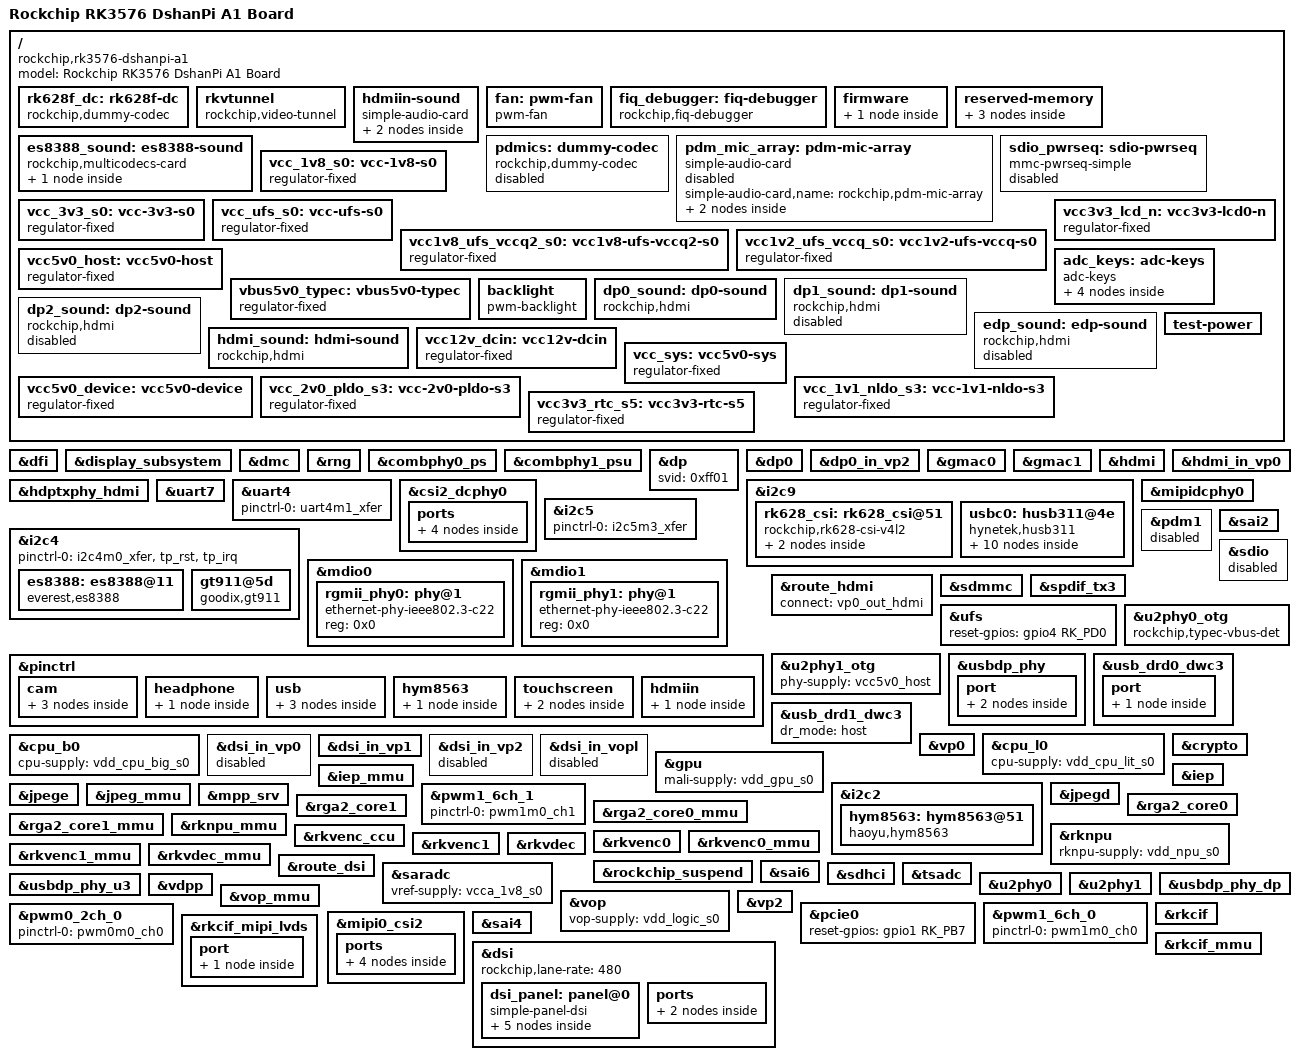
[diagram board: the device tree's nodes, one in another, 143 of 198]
// SPDX-License-Identifier: (GPL-2.0+ OR MIT)
/*
 * Copyright (c) 2024 Rockchip Electronics Co., Ltd.
 *
 */

/dts-v1/;

#include "rk3576.dtsi"
#include <dt-bindings/gpio/gpio.h>
#include <dt-bindings/pwm/pwm.h>
#include <dt-bindings/pinctrl/rockchip.h>
#include <dt-bindings/input/rk-input.h>
#include <dt-bindings/display/drm_mipi_dsi.h>
#include <dt-bindings/display/rockchip_vop.h>
#include <dt-bindings/sensor-dev.h>
#include <dt-bindings/usb/pd.h>
#include "rk3576-rk806.dtsi"

/ {

	model = "Rockchip RK3576 DshanPi A1 Board";
	compatible = "rockchip,rk3576-dshanpi-a1", "rockchip,rk3576";
	
	/delete-node/ chosen;
	
	rk628f_dc: rk628f-dc {
			compatible = "rockchip,dummy-codec";
			#sound-dai-cells = <0>;
			/*status = "okay";*/
	};

	rkvtunnel: rkvtunnel {
			compatible = "rockchip,video-tunnel";
			status = "okay";
	};

	hdmiin-sound {
			compatible = "simple-audio-card";
			simple-audio-card,format = "i2s";
			simple-audio-card,name = "rockchip,hdmiin";
			simple-audio-card,bitclock-master = <&dailink0_master>;
			simple-audio-card,frame-master = <&dailink0_master>;
			status = "okay";
			simple-audio-card,cpu {
					sound-dai = <&sai4>;
			};
			dailink0_master: simple-audio-card,codec {
					sound-dai = <&rk628f_dc>;
			};
	};

	fan: pwm-fan {
		status = "okay";
		compatible = "pwm-fan";
		#cooling-cells = <2>;
		pwms = <&pwm1_6ch_0 0 50000 1>;
		
		cooling-levels = <0 100 125 150 200 255>;
		
		rockchip,temp-trips = <
			40000    1
			50000    2
			60000    3
			65000    4
			70000    5
		>;
	};

	fiq_debugger: fiq-debugger {
		compatible = "rockchip,fiq-debugger";
		rockchip,serial-id = <0>;
		rockchip,wake-irq = <0>;
		/* If enable uart uses irq instead of fiq */
		rockchip,irq-mode-enable = <1>;
		rockchip,baudrate = <1500000>;  /* Only 115200 and 1500000 */
		interrupts = <GIC_SPI 389 IRQ_TYPE_LEVEL_LOW>;
		pinctrl-names = "default";
		pinctrl-0 = <&uart0m0_xfer>;
		status = "okay";
	};

	firmware {
		optee: optee {
			compatible = "linaro,optee-tz";
			method = "smc";
		};
	};

	reserved-memory {
		#address-cells = <2>;
		#size-cells = <2>;
		ranges;

		drm_logo: drm-logo@0 {
			compatible = "rockchip,drm-logo";
			reg = <0x0 0x0 0x0 0x0>;
		};

		drm_cubic_lut: drm-cubic-lut@0 {
			compatible = "rockchip,drm-cubic-lut";
			reg = <0x0 0x0 0x0 0x0>;
		};

		ramoops: ramoops@40110000 {
			compatible = "ramoops";
			/* 0x40110000 to 0x401f0000 is for ramoops */
			reg = <0x0 0x40110000 0x0 0xe0000>;
			boot-log-size = <0x8000>;	/* do not change */
			boot-log-count = <0x1>;		/* do not change */
			console-size = <0x80000>;
			pmsg-size = <0x30000>;
			ftrace-size = <0x00000>;
			record-size = <0x14000>;
		};
	};

	es8388_sound: es8388-sound {
		status = "okay";
		compatible = "rockchip,multicodecs-card";
		rockchip,card-name = "rockchip-es8388";
		hp-det-gpio = <&gpio0 RK_PA2 GPIO_ACTIVE_LOW>;
		io-channels = <&saradc 3>;
		io-channel-names = "adc-detect";
		keyup-threshold-microvolt = <1800000>;
		poll-interval = <100>;
		rockchip,pre-power-on-delay-ms = <30>;
		rockchip,post-power-down-delay-ms = <40>;
		rockchip,format = "i2s";
		rockchip,mclk-fs = <256>;
		rockchip,cpu = <&sai2>;
		rockchip,codec = <&es8388>;
		rockchip,audio-routing =
			"Speaker", "LOUT1",
			"Speaker", "ROUT1",
			"Speaker", "LOUT2",
			"Speaker", "ROUT2",
			"LINPUT1", "Main Mic",
			"RINPUT1", "Headset Mic",
			"LINPUT2", "Main Mic",
			"RINPUT2", "Headset Mic";
		pinctrl-names = "default";
		pinctrl-0 = <&hp_det>;
		play-pause-key {
			label = "playpause";
			linux,code = <KEY_PLAYPAUSE>;
			press-threshold-microvolt = <2000>;
		};
	};

	pdmics: dummy-codec {
		status = "disabled";
		compatible = "rockchip,dummy-codec";
		#sound-dai-cells = <0>;
	};

	pdm_mic_array: pdm-mic-array {
		status = "disabled";
		compatible = "simple-audio-card";
		simple-audio-card,name = "rockchip,pdm-mic-array";
		simple-audio-card,cpu {
			sound-dai = <&pdm1>;
		};
		simple-audio-card,codec {
			sound-dai = <&pdmics>;
		};
	};

	sdio_pwrseq: sdio-pwrseq {
		compatible = "mmc-pwrseq-simple";
		//pinctrl-names = "default";
		//pinctrl-0 = <&wifi_poweren_gpio>;

		/*
		 * On the module itself this is one of these (depending
		 * on the actual card populated):
		 * - SDIO_RESET_L_WL_REG_ON
		 * - PDN (power down when low)
		 */
		post-power-on-delay-ms = <200>;
		reset-gpios = <&gpio1 RK_PC6 GPIO_ACTIVE_LOW>;
		status = "disabled";
	};

	vcc_1v8_s0: vcc-1v8-s0 {
		compatible = "regulator-fixed";
		regulator-name = "vcc_1v8_s0";
		regulator-boot-on;
		regulator-always-on;
		regulator-min-microvolt = <1800000>;
		regulator-max-microvolt = <1800000>;
		vin-supply = <&vcc_1v8_s3>;
	};

	vcc_3v3_s0: vcc-3v3-s0 {
		compatible = "regulator-fixed";
		regulator-name = "vcc_3v3_s0";
		regulator-boot-on;
		regulator-always-on;
		regulator-min-microvolt = <3300000>;
		regulator-max-microvolt = <3300000>;
		vin-supply = <&vcc_3v3_s3>;
	};

	vcc_ufs_s0: vcc-ufs-s0 {
		compatible = "regulator-fixed";
		regulator-name = "vcc_ufs_s0";
		regulator-boot-on;
		regulator-always-on;
		regulator-min-microvolt = <3300000>;
		regulator-max-microvolt = <3300000>;
		vin-supply = <&vcc_sys>;
	};

	vcc1v8_ufs_vccq2_s0: vcc1v8-ufs-vccq2-s0 {
		compatible = "regulator-fixed";
		regulator-name = "vcc1v8_ufs_vccq2_s0";
		regulator-boot-on;
		regulator-always-on;
		regulator-min-microvolt = <1800000>;
		regulator-max-microvolt = <1800000>;
		vin-supply = <&vcc_1v8_s3>;
	};

	vcc1v2_ufs_vccq_s0: vcc1v2-ufs-vccq-s0 {
		compatible = "regulator-fixed";
		regulator-name = "vcc1v2_ufs_vccq_s0";
		regulator-boot-on;
		regulator-always-on;
		regulator-min-microvolt = <1200000>;
		regulator-max-microvolt = <1200000>;
		vin-supply = <&vcc_sys>;
	};

	vcc3v3_lcd_n: vcc3v3-lcd0-n {
		compatible = "regulator-fixed";
		regulator-name = "vcc3v3_lcd0_n";
		regulator-boot-on;
		enable-active-high;
		gpio = <&gpio0 RK_PC6 GPIO_ACTIVE_HIGH>;
		vin-supply = <&vcc_3v3_s0>;
	};

	vcc5v0_host: vcc5v0-host {
		compatible = "regulator-fixed";
		regulator-name = "vcc5v0_host";
		regulator-boot-on;
		regulator-always-on;
		regulator-min-microvolt = <5000000>;
		regulator-max-microvolt = <5000000>;
		enable-active-high;
		gpio = <&gpio0 RK_PC7 GPIO_ACTIVE_HIGH>;
		vin-supply = <&vcc5v0_device>;
		pinctrl-names = "default";
		pinctrl-0 = <&usb_host_pwren>;
	};

	vbus5v0_typec: vbus5v0-typec {
		compatible = "regulator-fixed";
		regulator-name = "vbus5v0_typec";
		regulator-min-microvolt = <5000000>;
		regulator-max-microvolt = <5000000>;
		enable-active-high;
		gpio = <&gpio1 RK_PC1 GPIO_ACTIVE_HIGH>;
		vin-supply = <&vcc5v0_device>;
		pinctrl-names = "default";
		pinctrl-0 = <&usb_otg0_pwren>;
	};

	adc_keys: adc-keys {
		compatible = "adc-keys";
		io-channels = <&saradc 1>;
		io-channel-names = "buttons";
		keyup-threshold-microvolt = <1800000>;
		poll-interval = <100>;

		vol-up-key {
			label = "volume up";
			linux,code = <KEY_VOLUMEUP>;
			press-threshold-microvolt = <17000>;
		};

		vol-down-key {
			label = "volume down";
			linux,code = <KEY_VOLUMEDOWN>;
			press-threshold-microvolt = <417000>;
		};

		menu-key {
			label = "menu";
			linux,code = <KEY_MENU>;
			press-threshold-microvolt = <890000>;
		};

		back-key {
			label = "back";
			linux,code = <KEY_BACK>;
			press-threshold-microvolt = <1235000>;
		};
	};

	backlight: backlight {
		compatible = "pwm-backlight";
		pwms = <&pwm0_2ch_0 0 25000 0>;
		brightness-levels = <
			  0  20  20  21  21  22  22  23
			 23  24  24  25  25  26  26  27
			 27  28  28  29  29  30  30  31
			 31  32  32  33  33  34  34  35
			 35  36  36  37  37  38  38  39
			 40  41  42  43  44  45  46  47
			 48  49  50  51  52  53  54  55
			 56  57  58  59  60  61  62  63
			 64  65  66  67  68  69  70  71
			 72  73  74  75  76  77  78  79
			 80  81  82  83  84  85  86  87
			 88  89  90  91  92  93  94  95
			 96  97  98  99 100 101 102 103
			104 105 106 107 108 109 110 111
			112 113 114 115 116 117 118 119
			120 121 122 123 124 125 126 127
			128 129 130 131 132 133 134 135
			136 137 138 139 140 141 142 143
			144 145 146 147 148 149 150 151
			152 153 154 155 156 157 158 159
			160 161 162 163 164 165 166 167
			168 169 170 171 172 173 174 175
			176 177 178 179 180 181 182 183
			184 185 186 187 188 189 190 191
			192 193 194 195 196 197 198 199
			200 201 202 203 204 205 206 207
			208 209 210 211 212 213 214 215
			216 217 218 219 220 221 222 223
			224 225 226 227 228 229 230 231
			232 233 234 235 236 237 238 239
			240 241 242 243 244 245 246 247
			248 249 250 251 252 253 254 255
		>;
		default-brightness-level = <200>;
	};

	dp0_sound: dp0-sound {
		status = "okay";
		compatible = "rockchip,hdmi";
		rockchip,mclk-fs = <512>;
		rockchip,card-name = "rockchip-dp0";
		rockchip,cpu = <&spdif_tx3>;
		rockchip,codec = <&dp0 1>;
		rockchip,jack-det;
	};

	dp1_sound: dp1-sound {
		status = "disabled";
		compatible = "rockchip,hdmi";
		rockchip,mclk-fs = <512>;
		rockchip,card-name = "rockchip-dp1";
		rockchip,cpu = <&spdif_tx3>;
		rockchip,codec = <&dp1 1>;
		rockchip,jack-det;
	};

	dp2_sound: dp2-sound {
		status = "disabled";
		compatible = "rockchip,hdmi";
		rockchip,mclk-fs = <512>;
		rockchip,card-name = "rockchip-dp2";
		rockchip,cpu = <&spdif_tx3>;
		rockchip,codec = <&dp2 1>;
		rockchip,jack-det;
	};

	edp_sound: edp-sound {
		status = "disabled";
		compatible = "rockchip,hdmi";
		rockchip,mclk-fs = <128>;
		rockchip,card-name = "rockchip-edp";
		rockchip,cpu = <&sai6>;
		rockchip,codec = <&edp 0>;
	};

	hdmi_sound: hdmi-sound {
		compatible = "rockchip,hdmi";
		rockchip,mclk-fs = <128>;
		rockchip,card-name = "rockchip-hdmi";
		rockchip,cpu = <&sai6>;
		rockchip,codec = <&hdmi>;
		rockchip,jack-det;
	};

	test-power {
		status = "okay";
	};

	vcc12v_dcin: vcc12v-dcin {
		compatible = "regulator-fixed";
		regulator-name = "vcc12v_dcin";
		regulator-always-on;
		regulator-boot-on;
		regulator-min-microvolt = <12000000>;
		regulator-max-microvolt = <12000000>;
	};

	vcc_sys: vcc5v0-sys {
		compatible = "regulator-fixed";
		regulator-name = "vcc_sys";
		regulator-always-on;
		regulator-boot-on;
		regulator-min-microvolt = <5000000>;
		regulator-max-microvolt = <5000000>;
		vin-supply = <&vcc12v_dcin>;
	};

	vcc5v0_device: vcc5v0-device {
		compatible = "regulator-fixed";
		regulator-name = "vcc5v0_device";
		regulator-always-on;
		regulator-boot-on;
		regulator-min-microvolt = <5000000>;
		regulator-max-microvolt = <5000000>;
		vin-supply = <&vcc12v_dcin>;
	};

	vcc_2v0_pldo_s3: vcc-2v0-pldo-s3 {
		compatible = "regulator-fixed";
		regulator-name = "vcc_2v0_pldo_s3";
		regulator-boot-on;
		regulator-always-on;
		regulator-min-microvolt = <2000000>;
		regulator-max-microvolt = <2000000>;
		vin-supply = <&vcc_sys>;
	};

	vcc_1v1_nldo_s3: vcc-1v1-nldo-s3 {
		compatible = "regulator-fixed";
		regulator-name = "vcc_1v1_nldo_s3";
		regulator-boot-on;
		regulator-always-on;
		regulator-min-microvolt = <1100000>;
		regulator-max-microvolt = <1100000>;
		vin-supply = <&vcc_sys>;
	};

	vcc3v3_rtc_s5: vcc3v3-rtc-s5 {
		compatible = "regulator-fixed";
		regulator-name = "vcc3v3_rtc_s5";
		regulator-boot-on;
		regulator-always-on;
		regulator-min-microvolt = <3300000>;
		regulator-max-microvolt = <3300000>;
		vin-supply = <&vcc_sys>;
	};
};



&dfi {
	status = "okay";
};

&display_subsystem {
	clocks = <&hdptxphy_hdmi>;
	clock-names = "hdmi0_phy_pll";
	memory-region = <&drm_logo>, <&drm_cubic_lut>;
	memory-region-names = "drm-logo", "drm-cubic-lut";
	/* devfreq = <&dmc>; */
};

&dmc {
	status = "okay";
	center-supply = <&vdd_ddr_s0>;
	mem-supply = <&vdd_logic_s0>;
};

&rng {
	status = "okay";
};

&combphy0_ps {
	status = "okay";
};

&combphy1_psu {
	status = "okay";
};

&dp {
	status = "okay";
	svid = <0xff01>;
};

&dp0 {
	status = "okay";
};

&dp0_in_vp2 {
	status = "okay";
};

&gmac0 {
	/* Use rgmii-rxid mode to disable rx delay inside Soc */
	phy-mode = "rgmii-rxid";
	clock_in_out = "output";

	snps,reset-gpio = <&gpio0 RK_PC2 GPIO_ACTIVE_LOW>;
	snps,reset-active-low;
	/* Reset time is 20ms, 100ms for rtl8211f */
	snps,reset-delays-us = <0 20000 100000>;

	pinctrl-names = "default";
	pinctrl-0 = <&eth0m0_miim
		     &eth0m0_tx_bus2
		     &eth0m0_rx_bus2
		     &eth0m0_rgmii_clk
		     &eth0m0_rgmii_bus>;

	tx_delay = <0x1b>;
	/* rx_delay = <0x3f>; */

	phy-handle = <&rgmii_phy0>;
	status = "okay";
};

&gmac1 {
	/* Use rgmii-rxid mode to disable rx delay inside Soc */
	phy-mode = "rgmii-rxid";
	clock_in_out = "output";

	snps,reset-gpio = <&gpio0 RK_PC5 GPIO_ACTIVE_LOW>;
	snps,reset-active-low;
	/* Reset time is 20ms, 100ms for rtl8211f */
	snps,reset-delays-us = <0 20000 100000>;

	pinctrl-names = "default";
	pinctrl-0 = <&eth1m0_miim
		     &eth1m0_tx_bus2
		     &eth1m0_rx_bus2
		     &eth1m0_rgmii_clk
		     &eth1m0_rgmii_bus>;

	tx_delay = <0x1a>;
	/* rx_delay = <0x3f>; */

	phy-handle = <&rgmii_phy1>;
	status = "okay";
};

&hdmi {
	status = "okay";
	enable-gpios = <&gpio2 RK_PB0 GPIO_ACTIVE_HIGH>;
	rockchip,sda-falling-delay-ns = <360>;
};

&hdmi_in_vp0 {
	status = "okay";
};

&hdptxphy_hdmi {
	status = "okay";
};

&uart7 {
	status = "okay";
	pinctrl-names = "default";
    pinctrl-0 = <&uart7m0_xfer &uart7m0_ctsn &uart7m0_rtsn>;
};

&uart4 {
	status = "okay";
	pinctrl-names = "default";
    pinctrl-0 = <&uart4m1_xfer>;
};

&csi2_dcphy0 {
	status = "okay";

	ports {
		#address-cells = <1>;
		#size-cells = <0>;
		port@0 {
			reg = <0>;
			#address-cells = <1>;
			#size-cells = <0>;

			hdmi_mipi_in: endpoint@1 {
				reg = <1>;
				remote-endpoint = <&hdmiin_out>;
				data-lanes = <1 2 3 4>;
			};
		};
		port@1 {
			reg = <1>;
			#address-cells = <1>;
			#size-cells = <0>;

			csidphy0_out: endpoint@0 {
				reg = <0>;
				remote-endpoint = <&mipi0_csi2_input>;
			};
		};
	};
};

&i2c9 {
	clock-frequency = <100000>;
	status = "okay";
	pinctrl-names = "default";
	pinctrl-0 = <&i2c9m1_xfer>;

	rk628_csi: rk628_csi@51 {
		compatible = "rockchip,rk628-csi-v4l2";
		status = "okay";
		reg = <0x51>;
		i2s-enable-default;
		power-domains = <&power RK3576_PD_VI>;
		interrupt-parent = <&gpio4>;
		interrupts = <RK_PB4 IRQ_TYPE_LEVEL_HIGH>;
		enable-gpios = <&gpio4 RK_PA3 GPIO_ACTIVE_HIGH>;
		reset-gpios = <&gpio4 RK_PA5 GPIO_ACTIVE_LOW>;
		plugin-det-gpios = <&gpio4 RK_PB5 GPIO_ACTIVE_LOW>;
		continues-clk = <1>;
		cec-enable;
		/*#sound-dai-cells = <0>;*/
		
		pinctrl-names = "default";
		pinctrl-0 = <&rk628_pin &ref_clk2_clk2>;
		assigned-clocks = <&cru REF_CLK2_OUT_PLL>;
		assigned-clock-rates = <24000000>;
		clocks = <&cru REF_CLK2_OUT_PLL>;
		clock-names = "soc_24M";
		
		rockchip,camera-module-index = <0>;
		rockchip,camera-module-facing = "back";
		rockchip,camera-module-name = "HDMI-MIPI1";
		rockchip,camera-module-lens-name = "RK628-CSI";
		
		port {
			hdmiin_out: endpoint {
				remote-endpoint = <&hdmi_mipi_in>;
				data-lanes = <1 2 3 4>;
			};
		};
    };

	usbc0: husb311@4e {
		compatible = "hynetek,husb311";
		reg = <0x4e>;
		interrupt-parent = <&gpio1>;
		interrupts = <RK_PC0 IRQ_TYPE_LEVEL_LOW>;
		pinctrl-names = "default";
		pinctrl-0 = <&usbc0_int>;
		vbus-supply = <&vbus5v0_typec>;
		status = "okay";

		port {
			usbc0_role_sw: endpoint {
				remote-endpoint = <&usb_drd0_role_switch>;
			};
		};

		usb_con: connector {
			compatible = "usb-c-connector";
			label = "USB-C";
			data-role = "dual";
			power-role = "dual";
			try-power-role = "sink";
			op-sink-microwatt = <1000000>;
			sink-pdos =
				<PDO_FIXED(5000, 1000, PDO_FIXED_USB_COMM)>;
			source-pdos =
				<PDO_FIXED(5000, 3000, PDO_FIXED_USB_COMM)>;
			mode-switch = <&dp>;

			altmodes {
				#address-cells = <1>;
				#size-cells = <0>;

				altmode@0 {
					reg = <0>;
					svid = <0xff01>;
					vdo = <0xffffffff>;
				};
			};

			ports {
				#address-cells = <1>;
				#size-cells = <0>;

				port@0 {
					reg = <0>;
					usbc0_orien_sw: endpoint {
						remote-endpoint = <&usbdp_phy_orientation_switch>;
					};
				};

				port@1 {
					reg = <1>;
					dp_altmode_mux: endpoint {
						remote-endpoint = <&usbdp_phy_dp_altmode_mux>;
					};
				};
			};
		};
	};
};


&i2c4 {
	status = "okay";
	pinctrl-names = "default";
    	pinctrl-0 = <&i2c4m0_xfer &tp_rst &tp_irq>;

	es8388: es8388@11 {
		status = "okay";
		#sound-dai-cells = <0>;
		compatible = "everest,es8388", "everest,es8323";
		reg = <0x11>;
		clocks = <&mclkout_sai2>;
		clock-names = "mclk";
		assigned-clocks = <&mclkout_sai2>;
		assigned-clock-rates = <12288000>;
		pinctrl-names = "default";
		pinctrl-0 = <&sai2m0_mclk>;
	};

	gt911@5d {
		compatible = "goodix,gt911";
		reg = <0x5d>;
		interrupt-parent = <&gpio4>;
		interrupts = <RK_PC6 IRQ_TYPE_EDGE_FALLING>;
		reset-gpios = <&gpio0 RK_PC1 GPIO_ACTIVE_LOW>;
		pinctrl-names = "default";
	};
};

&i2c5 {
	status = "okay";
	pinctrl-names = "default";
	pinctrl-0 = <&i2c5m3_xfer>;
};

&mdio0 {
	rgmii_phy0: phy@1 {
		compatible = "ethernet-phy-ieee802.3-c22";
		reg = <0x0>;
	};
};

&mdio1 {
	rgmii_phy1: phy@1 {
		compatible = "ethernet-phy-ieee802.3-c22";
		reg = <0x0>;
	};
};

&mipidcphy0 {
	status = "okay";
};

&pdm1 {
	status = "disabled";
	pinctrl-names = "default";
	pinctrl-0 = <&pdm1m1_clk0
		     &pdm1m1_clk1
		     &pdm1m1_sdi0
		     &pdm1m1_sdi1
		     &pdm1m1_sdi2
		     &pdm1m1_sdi3>;
};

&pinctrl {
	cam {
		mipicsi0_pwr: mipicsi0-pwr {
			rockchip,pins =
				/* camera power en */
				<3 RK_PB0 RK_FUNC_GPIO &pcfg_pull_none>;
		};

		mipicsi1_pwr: mipicsi1-pwr {
			rockchip,pins =
				/* camera power en */
				<3 RK_PC5 RK_FUNC_GPIO &pcfg_pull_none>;
		};

		mipidcphy0_pwr: mipidcphy0-pwr {
			rockchip,pins =
				/* camera power en */
				<3 RK_PC6 RK_FUNC_GPIO &pcfg_pull_none>;
		};
	};

	headphone {
		hp_det: hp-det {
			rockchip,pins = <0 RK_PA2 RK_FUNC_GPIO &pcfg_pull_up>;
		};
	};

	usb {
		usb_host_pwren: usb-host-pwren {
			rockchip,pins = <0 RK_PC7 RK_FUNC_GPIO &pcfg_pull_none>;
		};

		usb_otg0_pwren: usb-otg0-pwren {
			rockchip,pins = <0 RK_PD1 RK_FUNC_GPIO &pcfg_pull_none>;
		};

		usbc0_int: usbc0-int {
			rockchip,pins = <0 RK_PA5 RK_FUNC_GPIO &pcfg_pull_up>;
		};
	};

	hym8563 {
		hym8563_int: hym8563-int {
			rockchip,pins = <0 RK_PA0 RK_FUNC_GPIO &pcfg_pull_up>;
		};
	};

	touchscreen {
		tp_rst:tp-rst {
				rockchip,pins = <0 RK_PC1 RK_FUNC_GPIO &pcfg_pull_up>;
		};

		tp_irq:tp-irq {
				rockchip,pins = <4 RK_PC6 RK_FUNC_GPIO &pcfg_pull_none>;
		};
	};

	hdmiin {
		rk628_pin: rk628-pin {
			rockchip,pins = <4 RK_PB4 RK_FUNC_GPIO &pcfg_pull_none>,
					<4 RK_PA3 RK_FUNC_GPIO &pcfg_pull_none>,
					<4 RK_PA5 RK_FUNC_GPIO &pcfg_pull_none>,
					<4 RK_PB5 RK_FUNC_GPIO &pcfg_pull_none>;
		};
	};
};

&route_hdmi {
	status = "okay";
	connect = <&vp0_out_hdmi>;
};

&sai2 {
	status = "okay";
	pinctrl-names = "default";
	pinctrl-0 = <&sai2m0_lrck
		     &sai2m0_sclk
		     &sai2m0_sdi
		     &sai2m0_sdo>;
};

&sdio {
	max-frequency = <200000000>;
	no-sd;
	no-mmc;
	bus-width = <4>;
	disable-wp;
	cap-sd-highspeed;
	cap-sdio-irq;
	keep-power-in-suspend;
	mmc-pwrseq = <&sdio_pwrseq>;
	non-removable;
	pinctrl-names = "default";
	pinctrl-0 = <&sdmmc1m0_bus4 &sdmmc1m0_clk &sdmmc1m0_cmd>;
	sd-uhs-sdr104;
	status = "disabled";
};

&sdmmc {
	status = "okay";
};

&spdif_tx3 {
	status = "okay";
};

&ufs {
	status = "okay";
};

&u2phy0_otg {
	rockchip,typec-vbus-det;
};

&u2phy1_otg {
	phy-supply = <&vcc5v0_host>;
};

&usbdp_phy {
	orientation-switch;
	svid = <0xff01>;
	sbu1-dc-gpios = <&gpio2 RK_PA6 GPIO_ACTIVE_HIGH>;
	sbu2-dc-gpios = <&gpio2 RK_PA7 GPIO_ACTIVE_HIGH>;

	port {
		#address-cells = <1>;
		#size-cells = <0>;

		usbdp_phy_orientation_switch: endpoint@0 {
			reg = <0>;
			remote-endpoint = <&usbc0_orien_sw>;
		};

		usbdp_phy_dp_altmode_mux: endpoint@1 {
			reg = <1>;
			remote-endpoint = <&dp_altmode_mux>;
		};
	};
};

&usb_drd0_dwc3 {
	dr_mode = "otg";
	usb-role-switch;
	port {
		usb_drd0_role_switch: endpoint {
			remote-endpoint = <&usbc0_role_sw>;
		};
	};
};

&usb_drd1_dwc3 {
	dr_mode = "host";
	status = "okay";
};

&vp0 {
	status = "okay";
};

&cpu_l0 {
	cpu-supply = <&vdd_cpu_lit_s0>;
};

&cpu_b0 {
	cpu-supply = <&vdd_cpu_big_s0>;
};

&crypto {
	status = "okay";
};

&dsi_in_vp0 {
	status = "disabled";
};

&dsi_in_vp1 {
	status = "okay";
};

&dsi_in_vp2 {
	status = "disabled";
};

&dsi_in_vopl {
	status = "disabled";
};

&gpu {
	mali-supply = <&vdd_gpu_s0>;
	status = "okay";
};

&i2c2 {
	status = "okay";

	hym8563: hym8563@51 {
		compatible = "haoyu,hym8563";
		reg = <0x51>;
		#clock-cells = <0>;
		clock-frequency = <32768>;
		clock-output-names = "hym8563";
		pinctrl-names = "default";
		pinctrl-0 = <&hym8563_int>;
		interrupt-parent = <&gpio0>;
		interrupts = <RK_PA0 IRQ_TYPE_LEVEL_LOW>;
		wakeup-source;
	};
};

&iep {
	status = "okay";
};

&iep_mmu {
	status = "okay";
};

&jpegd {
	status = "okay";
};

&jpege {
	status = "okay";
};

&jpeg_mmu {
	status = "okay";
};

&mpp_srv {
	status = "okay";
};

&pwm1_6ch_1 {
	status = "okay";
	pinctrl-0 = <&pwm1m0_ch1>;
};

&rga2_core0 {
	status = "okay";
};

&rga2_core0_mmu {
	status = "okay";
};

&rga2_core1 {
	status = "okay";
};

&rga2_core1_mmu {
	status = "okay";
};

&rknpu {
	rknpu-supply = <&vdd_npu_s0>;
	status = "okay";
};

&rknpu_mmu {
	status = "okay";
};

&rkvenc_ccu {
	status = "okay";
};

&rkvenc0 {
	status = "okay";
};

&rkvenc0_mmu {
	status = "okay";
};

&rkvenc1 {
	status = "okay";
};

&rkvenc1_mmu {
	status = "okay";

};

&rkvdec {
	status = "okay";
};

&rkvdec_mmu {
	status = "okay";
};

&rockchip_suspend {
	status = "okay";
	rockchip,sleep-debug-en = <1>;

	rockchip,sleep-io-ret-config = <
		(0
		| RKPM_VCCIO3_RET_EN
		)
	>;

	rockchip,regulator-on-before-mem = <&vdd_npu_s0>;
};

&route_dsi {
	status = "okay";
};

&sai6 {
	status = "okay";
};

&saradc {
	status = "okay";
	vref-supply = <&vcca_1v8_s0>;
};

&sdhci {
	bus-width = <8>;
	no-sdio;
	no-sd;
	non-removable;
	max-frequency = <200000000>;
	mmc-hs400-1_8v;
	mmc-hs400-enhanced-strobe;
	full-pwr-cycle-in-suspend;
	status = "okay";
};

&sdmmc {
        max-frequency = <200000000>;
        pinctrl-0 = <&sdmmc0_clk &sdmmc0_cmd &sdmmc0_det &sdmmc0_bus4>;
        pinctrl-names = "default";
        no-sdio;
        no-mmc;
        bus-width = <4>;
        cap-mmc-highspeed;
        cap-sd-highspeed;
        disable-wp;
        sd-uhs-sdr104;
        vqmmc-supply = <&vccio_sd_s0>;
        vmmc-supply = <&vcc_3v3_s0>;
        status = "okay";
};

&tsadc {
	status = "okay";
};

&u2phy0 {
	status = "okay";
};

&u2phy1 {
	status = "okay";
};

&u2phy0_otg {
	status = "okay";
};

&u2phy1_otg {
	status = "okay";
};

&ufs {
	reset-gpios = <&gpio4 RK_PD0 GPIO_ACTIVE_HIGH>;
};

&usbdp_phy {
	status = "okay";
};

&usbdp_phy_dp {
	status = "okay";
};

&usbdp_phy_u3 {
	status = "okay";
};

&usb_drd0_dwc3 {
	status = "okay";
};

&vdpp {
	status = "okay";
};

&vop {
	status = "okay";
	vop-supply = <&vdd_logic_s0>;
};

&vop_mmu {
	status = "okay";
};

&vp2 {
	assigned-clocks = <&cru DCLK_VP2_SRC>;
	assigned-clock-parents = <&cru PLL_VPLL>;
};

/*******PCIE WIFI*******/
&pcie0 {
        reset-gpios = <&gpio1 RK_PB7 GPIO_ACTIVE_HIGH>;
	
        status = "okay";
};

/*******pwm-fan*******/
&pwm1_6ch_0 {
	status = "okay";
	pinctrl-0 = <&pwm1m0_ch0>;
};

&pwm0_2ch_0 {
        status = "okay";
        pinctrl-0 = <&pwm0m0_ch0>;
};

&mipi0_csi2 {
	status = "okay";

	ports {
		#address-cells = <1>;
		#size-cells = <0>;

		port@0 {
			reg = <0>;
			#address-cells = <1>;
			#size-cells = <0>;

			mipi0_csi2_input: endpoint@1 {
				reg = <1>;
				remote-endpoint = <&csidphy0_out>;
			};
		};

		port@1 {
			reg = <1>;
			#address-cells = <1>;
			#size-cells = <0>;

			mipi0_csi2_output: endpoint@0 {
				reg = <0>;
				remote-endpoint = <&cif_mipi_in0>;
			};
		};
	};
};

&rkcif {
	status = "okay";
};

&rkcif_mipi_lvds {
	status = "okay";

	port {
		cif_mipi_in0: endpoint {
			remote-endpoint = <&mipi0_csi2_output>;
		};
	};
};

&rkcif_mmu {
	status = "okay";
};

&sai4 {
	pinctrl-0 = <&sai4m0_lrck
		      &sai4m0_sclk
		      &sai4m0_sdi>;
	/*rockchip,sai-rx-wait-time-ms = <50>;*/
	status = "okay";
};

&dsi {
	status = "okay";
	rockchip,lane-rate = <480>;

	dsi_panel: panel@0 {
		status = "okay";
		compatible = "simple-panel-dsi";
		power-supply = <&vcc3v3_lcd_n>;
		reg = <0>;
		backlight = <&backlight>;

		prepare-delay-ms = <10>;
		reset-delay-ms = <40>;
		init-delay-ms = <40>;
		enable-delay-ms = <40>;
		disable-delay-ms = <50>;
		unprepare-delay-ms = <40>;

		reset-gpios = <&gpio0 RK_PD1 GPIO_ACTIVE_LOW>;
		pinctrl-names = "default";

		width-mm = <41>;
		height-mm = <31>;

		dsi,flags = <(MIPI_DSI_MODE_VIDEO | MIPI_DSI_MODE_VIDEO_BURST |
                              MIPI_DSI_MODE_LPM | MIPI_DSI_MODE_NO_EOT_PACKET)>;

		dsi,format = <MIPI_DSI_FMT_RGB888>;
		dsi,lanes = <2>;

		panel-init-sequence = [
			39 00 06 FF 77 01 00 00 13
			15 00 02 EF 08
			39 00 06 FF 77 01 00 00 10
			39 00 03 C0 2C 00
    			39 00 03 C1 10 0C
    			39 00 03 C2 21 0A
    			15 00 02 CC 10
			39 00 11 B0 00 12 9A 0E 12 07 0B 08 09 26 05 51 0F 69 30 1C
			39 00 11 B1 00 12 9B 0D 10 06 0B 09 08 25 03 50 0F 68 30 1C
    			39 00 06 FF 77 01 00 00 11
    			15 00 02 B0 5D
    			15 00 02 B1 66
    			15 00 02 B2 84
    			15 00 02 B3 80
    			15 00 02 B5 4E
    			15 00 02 B7 85
    			15 00 02 B8 20
    			15 00 02 C1 78
    			15 00 02 C2 78
    			15 00 02 D0 88
			39 00 04 E0 00 00 02
			39 00 0C E1 06 A0 08 A0 05 A0 07 A0 00 44 44
    			39 00 0D E2 00 00 44 44 01 A0 00 00 01 A0 00 00
    			39 00 05 E3 00 00 11 11
    			39 00 03 E4 44 44
    			39 00 11 E5 0D 79 0A A0 0F 7B 0A A0 09 75 0A A0 0B 77 0A A0
    			39 00 05 E6 00 00 11 11
    			39 00 03 E7 44 44
    			39 00 11 E8 0C 78 0A A0 0E 7A 0A A0 08 74 0A A0 0A 76 0A A0
    			39 00 03 E9 36 00
    			39 00 08 EB 00 01 E4 E4 44 88 40
    			39 00 11 ED FF 45 67 FA 01 2B AB FF FF BA B2 10 AF 76 54 FF
    			39 00 07 EF 10 0D 04 08 3F 1F
    			39 00 06 FF 77 01 00 00 00
    			39 00 06 FF 77 01 00 00 13
    			39 00 03 E8 00 0E
    			05 78 01 11     /* Sleep Out + 120 ms (0x78 = 120 ms) */
    			39 0A 03 E8 00 0C
    			39 00 03 E8 00 00
    			39 00 06 FF 77 01 00 00 00
    			05 14 01 29     /* Display ON + 20 ms (0x14 = 20 ms) */
		];

		panel-exit-sequence = [
			05 00 01 28
			05 78 01 10
		];

		display-timings {
			native-mode = <&timing0>;

			timing0: timing0 {
				clock-frequency = <11760000>;
				hactive = <480>;
				vactive = <360>;
				hfront-porch = <10>;
				hsync-len = <5>;
				hback-porch = <20>;
				vfront-porch = <5>;
				vsync-len = <5>;
				vback-porch = <10>;
				hsync-active = <0>;
				vsync-active = <0>;
				de-active = <0>;
				pixelclk-active = <0>;
			};
		};

		ports {
			#address-cells = <1>;
			#size-cells = <0>;

			port@0 {
				reg = <0>;
				panel_in_dsi: endpoint {
					remote-endpoint = <&dsi_out_panel>;
				};
			};
		};
	};

	ports {
		#address-cells = <1>;
		#size-cells = <0>;

		port@1 {
			reg = <1>;
			dsi_out_panel: endpoint {
				remote-endpoint = <&panel_in_dsi>;
			};
		};
	};
};
